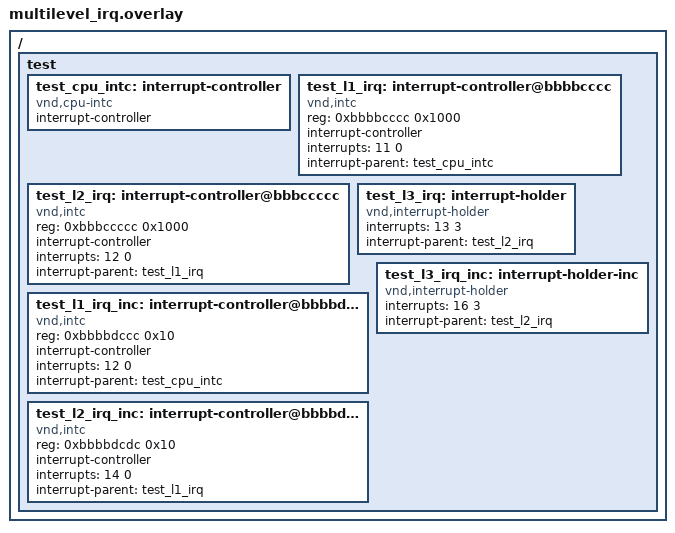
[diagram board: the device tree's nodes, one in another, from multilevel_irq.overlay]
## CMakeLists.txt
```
# SPDX-License-Identifier: Apache-2.0

cmake_minimum_required(VERSION 3.20.0)
find_package(Zephyr REQUIRED HINTS $ENV{ZEPHYR_BASE})
project(interrupt)

target_include_directories(app PRIVATE
  ${ZEPHYR_BASE}/kernel/include
  ${ZEPHYR_BASE}/arch/${ARCH}/include
  ${ZEPHYR_BASE}/arch/common/include
  )

target_sources(app PRIVATE
    src/prevent_irq.c
    src/interrupt_offload.c
    src/nested_irq.c
    )

target_sources_ifdef(CONFIG_DYNAMIC_INTERRUPTS app PRIVATE src/dynamic_isr.c)
target_sources_ifdef(CONFIG_X86 app PRIVATE src/regular_isr.c)
target_sources_ifdef(CONFIG_SHARED_INTERRUPTS app PRIVATE src/static_shared_irq.c)

if (CONFIG_SHARED_INTERRUPTS)
target_sources_ifdef(CONFIG_DYNAMIC_INTERRUPTS app PRIVATE src/dynamic_shared_irq.c)
endif()

if(CONFIG_MULTI_LEVEL_INTERRUPTS)
  target_sources_ifdef(CONFIG_DYNAMIC_INTERRUPTS app PRIVATE src/sw_isr_table.c)
  target_sources_ifdef(CONFIG_TEST_MULTILEVEL_IRQ app PRIVATE src/multilevel_irq.c)
endif()
```

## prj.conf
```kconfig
CONFIG_ZTEST=y
CONFIG_ZTEST_NEW_API=y
CONFIG_DYNAMIC_INTERRUPTS=y
CONFIG_MP_MAX_NUM_CPUS=1
CONFIG_THREAD_STACK_INFO=y
CONFIG_IRQ_OFFLOAD=y
```

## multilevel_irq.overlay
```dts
/*
 * Copyright (c) 2024 Meta Platforms
 * SPDX-License-Identifier: Apache-2.0
 */

/ {
	test {
		#address-cells = <0x1>;
		#size-cells = <0x1>;

		test_cpu_intc: interrupt-controller {
			compatible = "vnd,cpu-intc";
			#address-cells = <0>;
			#interrupt-cells = <0x01>;
			interrupt-controller;
		};

		test_l1_irq: interrupt-controller@bbbbcccc {
			compatible = "vnd,intc";
			reg = <0xbbbbcccc 0x1000>;
			interrupt-controller;
			#interrupt-cells = <2>;
			interrupts = <11 0>;
			interrupt-parent = <&test_cpu_intc>;
		};

		test_l2_irq: interrupt-controller@bbbccccc {
			compatible = "vnd,intc";
			reg = <0xbbbccccc 0x1000>;
			interrupt-controller;
			#interrupt-cells = <2>;
			interrupts = <12 0>;
			interrupt-parent = <&test_l1_irq>;
		};

		test_l3_irq: interrupt-holder {
			compatible = "vnd,interrupt-holder";
			status = "okay";
			interrupts = <13 3>;
			interrupt-parent = <&test_l2_irq>;
			interrupt-names = "test";
		};

		test_l1_irq_inc: interrupt-controller@bbbbdccc {
			compatible = "vnd,intc";
			reg = <0xbbbbdccc 0x10>;
			interrupt-controller;
			#interrupt-cells = <2>;
			interrupts = <12 0>;	/* +1 */
			interrupt-parent = <&test_cpu_intc>;
		};

		test_l2_irq_inc: interrupt-controller@bbbbdcdc {
			compatible = "vnd,intc";
			reg = <0xbbbbdcdc 0x10>;
			interrupt-controller;
			#interrupt-cells = <2>;
			interrupts = <14 0>;	/* +2 */
			interrupt-parent = <&test_l1_irq>;
		};

		test_l3_irq_inc: interrupt-holder-inc {
			compatible = "vnd,interrupt-holder";
			status = "okay";
			interrupts = <16 3>;	/* +3 */
			interrupt-parent = <&test_l2_irq>;
			interrupt-names = "test";
		};
	};
};
```

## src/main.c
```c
/*
 * Copyright (c) 2018 Intel Corporation
 *
 * SPDX-License-Identifier: Apache-2.0
 */

#include <ztest.h>

extern void test_isr_dynamic(void);
extern void test_nested_isr(void);
extern void test_prevent_interruption(void);
extern void test_isr_regular(void);
extern void test_isr_offload_job_multiple(void);
extern void test_isr_offload_job_identi(void);
extern void test_isr_offload_job(void);
extern void test_direct_interrupt(void);

void test_main(void)
{
	ztest_test_suite(interrupt_feature,
			ztest_unit_test(test_isr_dynamic),
			ztest_unit_test(test_nested_isr),
			ztest_unit_test(test_prevent_interruption),
			ztest_unit_test(test_isr_regular),
			ztest_unit_test(test_isr_offload_job_multiple),
			ztest_unit_test(test_isr_offload_job_identi),
			ztest_unit_test(test_isr_offload_job),
			ztest_unit_test(test_direct_interrupt)
			);
	ztest_run_test_suite(interrupt_feature);
}
```

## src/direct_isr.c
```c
/*
 * Copyright (c) 2021 Intel Corporation
 *
 * SPDX-License-Identifier: Apache-2.0
 */

#include <ztest.h>
#include "interrupt_util.h"

/*
 * Other arch has already been tested in testcase of gen_isr_table,
 * so we only test x86 and arch posix here.
 * And x86_64 is also not support this kind of interrupt, we skip it.
 */
#if (defined(CONFIG_X86) && !defined(CONFIG_X86_64)) ||\
	defined(CONFIG_ARCH_POSIX)

#if defined(CONFIG_X86)

#define TEST_DIRECT_IRQ_LINE_1	3
#define TEST_DIRECT_IRQ_LINE_2	4

#define TEST_DIRECT_IRQ_PRIO	0

#elif defined(CONFIG_ARCH_POSIX)
#define TEST_DIRECT_IRQ_LINE_1	5
#define TEST_DIRECT_IRQ_LINE_2	6

#define TEST_DIRECT_IRQ_PRIO	5

#endif

volatile uint32_t direct_int_executed[2];

ISR_DIRECT_DECLARE(direct_isr1)
{
	direct_int_executed[0]++;

	return 0;
}

ISR_DIRECT_DECLARE(direct_isr2)
{
	direct_int_executed[1]++;

	return 1;
}

/**
 * @brief Test direct interrupt function
 *
 * @details validate direct interrupt works as expected.
 * - Register two direct interrupt at build time.
 * - Trigger interrupt and check if isr handler has executed or not.
 * - Also check irq_enable and irq_disable works.
 *
 * @ingroup kernel_interrupt_tests
 *
 * @see IRQ_DIRECT_CONNECT(), ISR_DIRECT_DECLARE()
 */
void test_direct_interrupt(void)
{
	int trig_vec1, trig_vec2;

	IRQ_DIRECT_CONNECT(TEST_DIRECT_IRQ_LINE_1, TEST_DIRECT_IRQ_PRIO, direct_isr1, 0);
	IRQ_DIRECT_CONNECT(TEST_DIRECT_IRQ_LINE_2, TEST_DIRECT_IRQ_PRIO, direct_isr2, 0);

#if defined(CONFIG_X86)
	trig_vec1 = Z_IRQ_TO_INTERRUPT_VECTOR(TEST_DIRECT_IRQ_LINE_1);
	trig_vec2 = Z_IRQ_TO_INTERRUPT_VECTOR(TEST_DIRECT_IRQ_LINE_2);
#elif defined(CONFIG_ARCH_POSIX)
	trig_vec1 = TEST_DIRECT_IRQ_LINE_1;
	trig_vec2 = TEST_DIRECT_IRQ_LINE_2;
#endif
	TC_PRINT("irq(%d)=vector(%d)\n", TEST_DIRECT_IRQ_LINE_1, trig_vec1);
	TC_PRINT("irq(%d)=vector(%d)\n", TEST_DIRECT_IRQ_LINE_2, trig_vec2);

	irq_enable(TEST_DIRECT_IRQ_LINE_1);
	irq_enable(TEST_DIRECT_IRQ_LINE_2);

	zassert_true(direct_int_executed[0] == 0 &&
			direct_int_executed[1] == 0,
			"Both ISR should not execute");

	trigger_irq(trig_vec1);

	zassert_true(direct_int_executed[0] == 1 &&
			direct_int_executed[1] == 0,
			"ISR1 should execute");

	trigger_irq(trig_vec2);

	zassert_true(direct_int_executed[0] == 1 &&
			direct_int_executed[1] == 1,
			"Both ISR should execute");

	unsigned int key = irq_lock();

	/* trigger under irq locked */
	trigger_irq(trig_vec1);
	trigger_irq(trig_vec2);

	zassert_true(direct_int_executed[0] == 1 &&
			direct_int_executed[1] == 1,
			"Both ISR should not execute again");

	irq_unlock(key);

	/* interrupt serve after irq unlocked */
	zassert_true(direct_int_executed[0] == 2 &&
			direct_int_executed[1] == 2,
			"Both ISR should execute again(%d)(%d)",
			direct_int_executed[0], direct_int_executed[1]);

	/* trigger after irq unlocked */
	trigger_irq(trig_vec1);
	trigger_irq(trig_vec2);

	zassert_true(direct_int_executed[0] == 3 &&
			direct_int_executed[1] == 3,
			"Both ISR should execute again(%d)(%d)",
			direct_int_executed[0], direct_int_executed[1]);
}
#else
void test_direct_interrupt(void)
{
	ztest_test_skip();
}
#endif /* end defined(CONFIG_X86) || defined(CONFIG_ARCH_POSIX) */
```

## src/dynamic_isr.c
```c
/*
 * Copyright (c) 2018 Intel Corporation
 *
 * SPDX-License-Identifier: Apache-2.0
 */

#include <zephyr/ztest.h>
#include <zephyr/interrupt_util.h>

#define ISR_DYN_ARG	0xab249cfd

static unsigned int handler_has_run;
static uintptr_t handler_test_result;

static void dyn_isr(const void *arg)
{
	ARG_UNUSED(arg);
	handler_test_result = (uintptr_t)arg;
	handler_has_run++;
}

#if defined(CONFIG_GEN_SW_ISR_TABLE)
extern struct _isr_table_entry _sw_isr_table[];

#if defined(CONFIG_RISCV_RESERVED_IRQ_ISR_TABLES_OFFSET)
#define IRQ_OFFSET CONFIG_RISCV_RESERVED_IRQ_ISR_TABLES_OFFSET
#else
#define IRQ_OFFSET 0
#endif

/**
 * @brief Test dynamic ISR installation
 *
 * @ingroup kernel_interrupt_tests
 *
 * @details This routine locates an unused entry in the software ISR table,
 * installs a dynamic ISR to the unused entry by calling the dynamic
 * configured function, and verifies that the ISR is successfully installed
 * by checking the software ISR table entry.
 *
 * @see arch_irq_connect_dynamic()
 */
ZTEST(interrupt_feature, test_isr_dynamic)
{
	int i;
	const void *argval;

	for (i = 0; i < (CONFIG_NUM_IRQS - CONFIG_GEN_IRQ_START_VECTOR); i++) {
		if (_sw_isr_table[i].isr == z_irq_spurious) {
			break;
		}
	}

	zassert_true(_sw_isr_table[i].isr == z_irq_spurious,
		     "could not find slot for dynamic isr");

	printk("installing dynamic ISR for IRQ %d\n",
	       CONFIG_GEN_IRQ_START_VECTOR + i);

	argval = (const void *)&i;
	arch_irq_connect_dynamic(i + CONFIG_GEN_IRQ_START_VECTOR, 0, dyn_isr,
				 argval, 0);

	zassert_true(_sw_isr_table[i + IRQ_OFFSET].isr == dyn_isr &&
		     _sw_isr_table[i + IRQ_OFFSET].arg == argval,
		     "dynamic isr did not install successfully");
}
#else
/*
 * For testing arch such as x86, x86_64 and posix which support dynamic
 * interrupt but without SW ISR table, we test it by applying for a
 * dynamic interrupt and then trigger it to check if happened correctly.
 */
#if defined(CONFIG_X86)
#define IV_IRQS 32	/* start of vectors available for x86 IRQs */
#define TEST_IRQ_DYN_LINE 25

#elif defined(CONFIG_ARCH_POSIX)
#define TEST_IRQ_DYN_LINE 5
#endif

ZTEST(interrupt_feature, test_isr_dynamic)
{
	int vector_num;

	/**TESTPOINT: configuration of interrupts dynamically at runtime */
	vector_num = arch_irq_connect_dynamic(TEST_IRQ_DYN_LINE, 1, dyn_isr,
				 (void *)ISR_DYN_ARG, 0);

#if defined(CONFIG_X86_64)
/* The isr table for x86_64 is visiable, so check it up here */
extern void (*x86_irq_funcs[])(const void *);
extern const void *x86_irq_args[];

	zassert_true(x86_irq_funcs[vector_num - IV_IRQS] == dyn_isr &&
		     x86_irq_args[vector_num - IV_IRQS] == (void *)ISR_DYN_ARG,
		     "dynamic isr did not install successfully");
#endif

	TC_PRINT("vector(%d)\n", vector_num);
	zassert_true(vector_num > 0,
			"irq connect dynamic failed");

	zassert_equal(handler_has_run, 0,
			"handler has run before interrupt trigger");

	irq_enable(TEST_IRQ_DYN_LINE);

	trigger_irq(vector_num);

	zassert_equal(handler_has_run, 1,
			"interrupt triggered but handler has not run(%d)",
			handler_has_run);

	/**TESTPOINT: pass word-sized parameter to interrupt */
	zassert_equal(handler_test_result, ISR_DYN_ARG,
			"parameter(0x%" PRIxPTR ") in handler is not correct",
			handler_test_result);

	trigger_irq(vector_num);

	/**TESTPOINT: interrupt triggered again */
	zassert_equal(handler_has_run, 2,
			"interrupt triggered but handler has not run(%d)",
			handler_has_run);

	irq_disable(TEST_IRQ_DYN_LINE);
}
#endif /* CONFIG_GEN_SW_ISR_TABLE */
```

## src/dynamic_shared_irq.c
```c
/*
 * Copyright 2023 NXP
 *
 * SPDX-License-Identifier: Apache-2.0
 */

#include "test_shared_irq.h"

struct shared_irq_fixture {
	unsigned int irq1;
	unsigned int irq2;
	unsigned int irq1_table_idx;
	unsigned int irq2_table_idx;
	unsigned int irq_priority;
};

static struct shared_irq_fixture fixture;

static void reset_test_vector(void)
{
	int i;

	for (i = 0; i < TEST_VECTOR_SIZE; i++) {
		test_vector[i] = 0;
	}
}

static void dynamic_shared_irq_suite_after(void *data)
{
	ARG_UNUSED(data);

	/* note: no need to check the state of the SW ISR tables after
	 * all these disconnect operations. If there's something wrong
	 * it should be detected by dynamic_shared_irq_suite_before().
	 */
	arch_irq_disconnect_dynamic(fixture.irq1, fixture.irq_priority,
				    test_isr_0, 0, 0);
	arch_irq_disconnect_dynamic(fixture.irq1, fixture.irq_priority,
				    test_isr_1, (void *)1, 0);
	arch_irq_disconnect_dynamic(fixture.irq2, fixture.irq_priority,
				    test_isr_2, (void *)2, 0);
}

static void dummy_isr(const void *data)
{
	ARG_UNUSED(data);

	test_vector[0] = TEST_DUMMY_ISR_VAL;
}

static unsigned int get_irq_slot(unsigned int start)
{
	unsigned int i, table_idx;

	for (i = start; i <= CONFIG_GEN_IRQ_START_VECTOR + CONFIG_NUM_IRQS - 1; i++) {
		table_idx = i - CONFIG_GEN_IRQ_START_VECTOR;

		if (_sw_isr_table[table_idx].isr == &z_irq_spurious) {
			test_vector[0] = 0;

			/* check to see if we can trigger this IRQ */
			arch_irq_connect_dynamic(i, IRQ_PRIORITY, dummy_isr,
						 NULL, IRQ_FLAGS);
			irq_enable(i);
			trigger_irq(i);

			/* wait a bit */
			k_busy_wait(100);

			if (test_vector[0] == TEST_DUMMY_ISR_VAL) {
				/* found a valid INTID */
				irq_disable(i);

				arch_irq_disconnect_dynamic(i, IRQ_PRIORITY,
							    dummy_isr, NULL, 0);
				return i;
			}
		}
	}

	return TEST_INVALID_IRQ;
}

#if defined(CONFIG_RISCV_RESERVED_IRQ_ISR_TABLES_OFFSET)
#define TABLE_OFFSET CONFIG_RISCV_RESERVED_IRQ_ISR_TABLES_OFFSET
#else
#define TABLE_OFFSET 0
#endif

static void *dynamic_shared_irq_suite_setup(void)
{
	fixture.irq1 = get_irq_slot(CONFIG_GEN_IRQ_START_VECTOR + TABLE_OFFSET);
	zassert_true(fixture.irq1 != TEST_INVALID_IRQ,
		     "no suitable value found for irq1");
	fixture.irq2 = get_irq_slot(fixture.irq1 + 1);
	zassert_true(fixture.irq2 != TEST_INVALID_IRQ,
		     "no suitable value found for irq2");
	fixture.irq_priority = IRQ_PRIORITY;

	fixture.irq1_table_idx = fixture.irq1 - CONFIG_GEN_IRQ_START_VECTOR;
	fixture.irq2_table_idx = fixture.irq2 - CONFIG_GEN_IRQ_START_VECTOR;

	return NULL;
}

static void dynamic_shared_irq_suite_before(void *data)
{
	ARG_UNUSED(data);

	arch_irq_connect_dynamic(fixture.irq1, fixture.irq_priority,
				 test_isr_0, 0, IRQ_FLAGS);

	zassert_true(_sw_isr_table[fixture.irq1_table_idx + TABLE_OFFSET].isr == test_isr_0,
		     "wrong _sw_isr_table ISR at irq1");
	zassert_true(!_sw_isr_table[fixture.irq1_table_idx + TABLE_OFFSET].arg,
		     "wrong _sw_isr_table argument at irq1");
	zassert_true(!z_shared_sw_isr_table[fixture.irq1_table_idx + TABLE_OFFSET].client_num,
		     "wrong client number at irq1");

	arch_irq_connect_dynamic(fixture.irq1, fixture.irq_priority,
				 test_isr_1, (void *)1, IRQ_FLAGS);

	zassert_true(_sw_isr_table[fixture.irq1_table_idx + TABLE_OFFSET].isr == z_shared_isr,
		     "wrong _sw_isr_table ISR at irq1");
	zassert_true(_sw_isr_table[fixture.irq1_table_idx + TABLE_OFFSET].arg ==
		     &z_shared_sw_isr_table[fixture.irq1_table_idx + TABLE_OFFSET],
		     "wrong _sw_isr_table argument at irq1");
	zassert_true(z_shared_sw_isr_table[fixture.irq1_table_idx + TABLE_OFFSET].client_num == 2,
		     "wrong client number at irq1");

	zassert_true(client_exists_at_index(test_isr_0, 0, fixture.irq1_table_idx + TABLE_OFFSET,
					    0),
		     "unexpected client data for irq1, index 0");
	zassert_true(client_exists_at_index(test_isr_1, (void *)1,
		     fixture.irq1_table_idx + TABLE_OFFSET, 1),
		     "unexpected client data for irq1, index 1");

	arch_irq_connect_dynamic(fixture.irq2, fixture.irq_priority,
				 test_isr_2, (void *)2, IRQ_FLAGS);

	zassert_true(_sw_isr_table[fixture.irq2_table_idx + TABLE_OFFSET].isr == test_isr_2,
		     "wrong _sw_isr_table ISR at irq2");
	zassert_true(_sw_isr_table[fixture.irq2_table_idx + TABLE_OFFSET].arg == (void *)2,
		     "wrong _sw_isr_table argument at irq2");
	zassert_true(!z_shared_sw_isr_table[fixture.irq2_table_idx + TABLE_OFFSET].client_num,
		     "wrong client number at irq2");

	reset_test_vector();
}

/**
 * @brief Test writing to a vector with a shared interrupt
 *
 * @ingroup kernel_interrupt_tests
 *
 * @details This tests if interrupts are dynamically shared successfully
 * (i.e: multiple ISR/arg pairs are called whenever the interrupt
 * they were registered for is triggered).
 */
ZTEST(shared_irq_feature, test_dynamic_shared_irq_write)
{
	int i;

	irq_enable(fixture.irq1);
	irq_enable(fixture.irq2);

	trigger_irq(fixture.irq1);
	trigger_irq(fixture.irq2);

	/* wait 5ms before checking the results */
	k_busy_wait(5000);

	for (i = 0; i < TEST_VECTOR_SIZE; i++) {
		zassert_true(test_vector[i] == result_vector[i],
			     "wrong test_vector value at %d: 0x%x vs 0x%x",
			     i, test_vector[i], result_vector[i]);
	}

	irq_disable(fixture.irq1);
	irq_disable(fixture.irq2);
}

/**
 * @brief Test writing to a vector after an ISR/arg disconnect.
 *
 * @ingroup kernel_interrupt_tests
 *
 * @details This tests if ISR/arg pairs are disconnected successfully
 * and the interrupts are "unshared" whenever a single ISR/arg pair is
 * left.
 */
ZTEST(shared_irq_feature, test_dynamic_shared_irq_disconnect_write)
{
	int i;

	/* remove test_isr_0/NULL pair. After this statement we expect
	 * irq1 to be unshared.
	 */
	arch_irq_disconnect_dynamic(fixture.irq1, fixture.irq_priority,
				    test_isr_0, 0, 0);

	zassert_true(_sw_isr_table[fixture.irq1_table_idx + TABLE_OFFSET].isr == test_isr_1,
		     "wrong _sw_isr_table ISR at irq1");
	zassert_true(_sw_isr_table[fixture.irq1_table_idx + TABLE_OFFSET].arg == (void *)1,
		     "wrong _sw_isr_table arg at irq1");
	zassert_true(!z_shared_sw_isr_table[fixture.irq1_table_idx + TABLE_OFFSET].client_num,
		     "wrong client number at irq1");

	irq_enable(fixture.irq1);
	trigger_irq(fixture.irq1);

	/* wait 5ms before checking the results */
	k_busy_wait(5000);

	for (i = 0; i < TEST_VECTOR_SIZE; i++) {
		if (i == 1) {
			zassert_true(test_vector[i] == result_vector[i],
				     "wrong test_vector at %d: 0x%x vs 0x%x",
				     i, test_vector[i], result_vector[i]);
			continue;
		}

		zassert_true(!test_vector[i],
			     "wrong test_vector value at %d: 0x%x vs 0x%x",
			     i, test_vector[i], result_vector[i]);
	}

	irq_disable(fixture.irq1);
}

ZTEST_SUITE(shared_irq_feature, NULL,
	    dynamic_shared_irq_suite_setup,
	    dynamic_shared_irq_suite_before,
	    dynamic_shared_irq_suite_after,
	    NULL);
```

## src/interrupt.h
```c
/*
 * Copyright (c) 2018 Intel Corporation
 *
 * SPDX-License-Identifier: Apache-2.0
 */

#include <ztest.h>
#include <irq_offload.h>
#include <kernel_structs.h>


#if defined(CONFIG_CPU_CORTEX_M)
#include <arch/arm/aarch32/cortex_m/cmsis.h>

static u32_t get_available_nvic_line(u32_t initial_offset)
{
	int i;

	for (i = initial_offset - 1; i >= 0; i--) {

		if (NVIC_GetEnableIRQ(i) == 0) {
			/*
			 * Interrupts configured statically with IRQ_CONNECT(.)
			 * are automatically enabled. NVIC_GetEnableIRQ()
			 * returning false, here, implies that the IRQ line is
			 * either not implemented or it is not enabled, thus,
			 * currently not in use by Zephyr.
			 */

			/* Set the NVIC line to pending. */
			NVIC_SetPendingIRQ(i);

			if (NVIC_GetPendingIRQ(i)) {
				/* If the NVIC line is pending, it is
				 * guaranteed that it is implemented.
				 */
				break;
			}
		}
	}

	ztest_true(i >= 0, "No available IRQ line\n");

	return i;
}

static void trigger_irq(int irq)
{
	printk("Triggering irq : %d\n", irq);
#if defined(CONFIG_SOC_TI_LM3S6965_QEMU) || defined(CONFIG_CPU_CORTEX_M0) \
	|| defined(CONFIG_CPU_CORTEX_M0PLUS)
	NVIC_SetPendingIRQ(irq);
#else
	NVIC->STIR = irq;
#endif
}

#elif defined(CONFIG_RISCV)
static void trigger_irq(int irq)
{
	u32_t mip;

	printk("Triggering irq : %d\n", irq);
	__asm__ volatile ("csrrs %0, mip, %1\n"
			: "=r" (mip)
			: "r" (1 << irq));
}

#elif defined(CONFIG_CPU_ARCV2)
static void trigger_irq(int irq)
{
	printk("Triggering irq : %d\n", irq);
	z_arc_v2_aux_reg_write(_ARC_V2_AUX_IRQ_HINT, irq);
}
#else
/* for not supported architecture */
#define NO_TRIGGER_FROM_SW
#endif
```

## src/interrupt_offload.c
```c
/*
 * Copyright (c) 2021 Intel Corporation
 *
 * SPDX-License-Identifier: Apache-2.0
 */

#include <zephyr/ztest.h>
#include <zephyr/irq_offload.h>
#include <zephyr/interrupt_util.h>
#if defined(CONFIG_ARCH_POSIX)
#include <soc.h>
#endif

#define STACK_SIZE	1024
#define NUM_WORK	4

static struct k_work offload_work[NUM_WORK];
static struct k_work_q wq_queue;
static K_THREAD_STACK_DEFINE(wq_stack, STACK_SIZE);
static K_THREAD_STACK_DEFINE(tstack, STACK_SIZE);
static struct k_thread tdata;

static struct k_sem sync_sem;
static struct k_sem end_sem;
static bool wait_for_end;
static atomic_t submit_success;
static atomic_t offload_job_cnt;

/*
 * This global variable control if the priority of offload job
 * is greater than the original thread.
 */
static bool offload_job_prio_higher;

static volatile int orig_t_keep_run;

/* record the initialized interrupt vector for reuse */
static int vector_num;

enum {
	TEST_OFFLOAD_MULTI_JOBS,
	TEST_OFFLOAD_IDENTICAL_JOBS
};

struct interrupt_param {
	struct k_work *work;
};

static struct interrupt_param irq_param;

/* thread entry of doing offload job */
static void entry_offload_job(struct k_work *work)
{
	if (offload_job_prio_higher) {
		/*TESTPOINT: offload thread run right after irq end.*/
		zassert_equal(orig_t_keep_run, 0,
			"the offload did not run immediately.");
	} else {
		/*TESTPOINT: original thread run right after irq end.*/
		zassert_equal(orig_t_keep_run, 1,
			"the offload did not run immediately.");
	}

	atomic_inc(&offload_job_cnt);
	k_sem_give(&end_sem);
}

/* offload work to work queue */
void isr_handler(const void *param)
{
	struct k_work *work = ((struct interrupt_param *)param)->work;

	zassert_not_null(work, "kwork should not be NULL");

	orig_t_keep_run = 0;

	/* If the work is busy, we don't submit it. */
	if (!k_work_busy_get(work)) {
		zassert_equal(k_work_submit_to_queue(&wq_queue, work),
				1, "kwork not submitted or queued");

		atomic_inc(&submit_success);
	}
}

#if defined(CONFIG_DYNAMIC_INTERRUPTS)
/*
 * So far, we only test x86 and arch posix by real dynamic interrupt.
 * Other arch will be add later.
 */
#if defined(CONFIG_X86)
#define TEST_IRQ_DYN_LINE 26

#elif defined(CONFIG_ARCH_POSIX)
#if defined(OFFLOAD_SW_IRQ)
#define TEST_IRQ_DYN_LINE OFFLOAD_SW_IRQ
#else
#define TEST_IRQ_DYN_LINE 0
#endif

#elif defined(CONFIG_MICROBLAZE)
#define TEST_IRQ_DYN_LINE 1
#else
#define TEST_IRQ_DYN_LINE 0
#endif

#endif

static void init_dyn_interrupt(void)
{
	/* If we cannot get a dynamic interrupt, skip test. */
	if (TEST_IRQ_DYN_LINE == 0) {
		ztest_test_skip();
	}

	/* We just initialize dynamic interrupt once, then reuse them */
	if (!vector_num) {
		vector_num = irq_connect_dynamic(TEST_IRQ_DYN_LINE, 1,
					isr_handler, (void *)&irq_param, 0);
	}

	TC_PRINT("vector(%d)\n", vector_num);
	zassert_true(vector_num > 0, "no vector can be used");
	irq_enable(TEST_IRQ_DYN_LINE);
}

static void trigger_offload_interrupt(const bool real_irq, void *work)
{
	irq_param.work = work;

	if (real_irq) {
		trigger_irq(vector_num);
	} else {
		irq_offload((irq_offload_routine_t)&isr_handler, &irq_param);
	}
}

static void t_running(void *p1, void *p2, void *p3)
{
	ARG_UNUSED(p1);
	ARG_UNUSED(p2);
	ARG_UNUSED(p3);

	k_sem_give(&sync_sem);

	while (wait_for_end == false) {
		orig_t_keep_run = 1;
		k_usleep(150);
	}
}

static void init_env(int real_irq)
{
	static bool wq_already_start;

	/* semaphore used to sync the end */
	k_sem_init(&sync_sem, 0, 1);
	k_sem_init(&end_sem, 0, NUM_WORK);

	/* initialize global variables */
	submit_success = 0;
	offload_job_cnt = 0;
	orig_t_keep_run = 0;
	wait_for_end = false;

	/* initialize the dynamic interrupt while using it */
	if (real_irq && !vector_num) {
		init_dyn_interrupt();
	}

	/* initialize all the k_work */
	for (int i = 0; i < NUM_WORK; i++) {
		k_work_init(&offload_work[i], entry_offload_job);
	}

	/* start a work queue thread if not existing */
	if (!wq_already_start) {
		k_work_queue_start(&wq_queue, wq_stack, STACK_SIZE,
		K_PRIO_PREEMPT(1), NULL);

		wq_already_start = true;
	}
}

static void run_test_offload(int case_type, int real_irq)
{
	int thread_prio = K_PRIO_PREEMPT(0);

	/* initialize the global variables */
	init_env(real_irq);

	/* set priority of offload job higher than thread */
	if (offload_job_prio_higher) {
		thread_prio = K_PRIO_PREEMPT(2);
	}

	k_tid_t tid = k_thread_create(&tdata, tstack, STACK_SIZE,
			t_running,
			NULL, NULL, NULL, thread_prio,
			K_INHERIT_PERMS, K_NO_WAIT);

	/* wait for thread start */
	k_sem_take(&sync_sem, K_FOREVER);

	for (int i = 0; i < NUM_WORK; i++) {

		switch (case_type) {
		case TEST_OFFLOAD_MULTI_JOBS:
			trigger_offload_interrupt(real_irq,
					(void *)&offload_work[i]);
		break;
		case TEST_OFFLOAD_IDENTICAL_JOBS:
			trigger_offload_interrupt(real_irq,
					(void *)&offload_work[0]);
		break;
		default:
			ztest_test_fail();
		}
	}
	/* wait for all offload job complete */
	for (int i = 0; i < atomic_get(&submit_success); i++) {
		k_sem_take(&end_sem, K_FOREVER);
	}

	zassert_equal(submit_success, offload_job_cnt,
			"submitted job unmatch offload");

	/* notify the running thread to end */
	wait_for_end = true;

	k_thread_join(tid, K_FOREVER);
}

/**
 * @brief Test interrupt offload work to multiple jobs
 *
 * @ingroup kernel_interrupt_tests
 *
 * @details Validate isr can offload workload to multi work queue, and:
 *
 * - If the priority of the original thread < offload job, offload jobs
 *   could execute immediately.
 *
 * - If the priority of the original thread >= offload job, offload
 *   jobs will not execute immediately.
 *
 * We test this by irq_offload().
 */
ZTEST(interrupt_feature, test_isr_offload_job_multiple)
{
	offload_job_prio_higher = false;
	run_test_offload(TEST_OFFLOAD_MULTI_JOBS, false);

	offload_job_prio_higher = true;
	run_test_offload(TEST_OFFLOAD_MULTI_JOBS, false);
}

/**
 * @brief Test interrupt offload work to identical jobs
 *
 * @ingroup kernel_interrupt_tests
 *
 * @details Validate isr can offload workload to work queue, and all
 * the offload jobs use the same thread entry, and:
 *
 * - If the priority of the original thread < offload job, offload jobs
 *   could execute immediately.
 *
 * - If the priority of the original thread >= offload job, offload
 *   jobs will not execute immediately.
 *
 * We test this by irq_offload().
 */
ZTEST(interrupt_feature, test_isr_offload_job_identi)
{
	offload_job_prio_higher = false;
	run_test_offload(TEST_OFFLOAD_IDENTICAL_JOBS, false);

	offload_job_prio_higher = true;
	run_test_offload(TEST_OFFLOAD_IDENTICAL_JOBS, false);
}

/**
 * @brief Test interrupt offload work by dynamic interrupt
 *
 * @ingroup kernel_interrupt_tests
 *
 * @details Validate isr can offload workload to work queue, and the
 * offload jobs could execute immediately base on it's priority.
 * We test this by dynamic interrupt.
 */
ZTEST(interrupt_feature, test_isr_offload_job)
{
	if (!IS_ENABLED(CONFIG_DYNAMIC_INTERRUPTS)) {
		ztest_test_skip();
	}

	offload_job_prio_higher = true;
	run_test_offload(TEST_OFFLOAD_MULTI_JOBS, true);
	run_test_offload(TEST_OFFLOAD_IDENTICAL_JOBS, true);
}
```

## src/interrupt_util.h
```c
/*
 * Copyright (c) 2018 Intel Corporation
 *
 * SPDX-License-Identifier: Apache-2.0
 */

#ifndef INTERRUPT_UTIL_H_
#define INTERRUPT_UTIL_H_

#include <ztest.h>

#define MS_TO_US(ms)  (ms * USEC_PER_MSEC)

#if defined(CONFIG_CPU_CORTEX_M)
#include <arch/arm/aarch32/cortex_m/cmsis.h>

static inline uint32_t get_available_nvic_line(uint32_t initial_offset)
{
	int i;

	for (i = initial_offset - 1; i >= 0; i--) {

		if (NVIC_GetEnableIRQ(i) == 0) {
			/*
			 * Interrupts configured statically with IRQ_CONNECT(.)
			 * are automatically enabled. NVIC_GetEnableIRQ()
			 * returning false, here, implies that the IRQ line is
			 * either not implemented or it is not enabled, thus,
			 * currently not in use by Zephyr.
			 */

			/* Set the NVIC line to pending. */
			NVIC_SetPendingIRQ(i);

			if (NVIC_GetPendingIRQ(i)) {
				/*
				 * If the NVIC line is pending, it is
				 * guaranteed that it is implemented; clear the
				 * line.
				 */
				NVIC_ClearPendingIRQ(i);

				if (!NVIC_GetPendingIRQ(i)) {
					/*
					 * If the NVIC line can be successfully
					 * un-pended, it is guaranteed that it
					 * can be used for software interrupt
					 * triggering. Return the NVIC line
					 * number.
					 */
					break;
				}
			}
		}
	}

	zassert_true(i >= 0, "No available IRQ line\n");

	return i;
}

static inline void trigger_irq(int irq)
{
	printk("Triggering irq : %d\n", irq);
#if defined(CONFIG_SOC_TI_LM3S6965_QEMU) || defined(CONFIG_CPU_CORTEX_M0) \
	|| defined(CONFIG_CPU_CORTEX_M0PLUS) || defined(CONFIG_CPU_CORTEX_M1)
	NVIC_SetPendingIRQ(irq);
#else
	NVIC->STIR = irq;
#endif
}

#elif defined(CONFIG_GIC)
#include <drivers/interrupt_controller/gic.h>
#include <dt-bindings/interrupt-controller/arm-gic.h>

static inline void trigger_irq(int irq)
{
	printk("Triggering irq : %d\n", irq);

	/* Ensure that the specified IRQ number is a valid SGI interrupt ID */
	zassert_true(irq <= 15, "%u is not a valid SGI interrupt ID", irq);

	/*
	 * Generate a software generated interrupt and forward it to the
	 * requesting CPU.
	 */
#if CONFIG_GIC_VER <= 2
	sys_write32(GICD_SGIR_TGTFILT_REQONLY | GICD_SGIR_SGIINTID(irq),
		    GICD_SGIR);
#else
	gic_raise_sgi(irq, GET_MPIDR(), BIT(MPIDR_TO_CORE(GET_MPIDR())));
#endif
}

#elif defined(CONFIG_ARC)
static inline void trigger_irq(int irq)
{
	printk("Triggering irq : %d\n", irq);
	z_arc_v2_aux_reg_write(_ARC_V2_AUX_IRQ_HINT, irq);
}

#elif defined(CONFIG_X86)

#define TEST_IRQ_DYN_LINE 16
#define TEST_DYNAMIC_VECTOR     TEST_IRQ_DYN_LINE+32

static inline void trigger_irq(int irq)
{
	int vector = irq + 32;

/*
 * Trigger an interrupt of x86 under gcov code coverage report enabled,
 * which means GCC optimization will be -O0, so need to hard code the
 * immediate number for INT instruction. Otherwise, an build error
 * happends and shows:
 * "error: 'asm' operand 0 probably does not match constraints" and
 * "error: impossible constraint in 'asm'"
 */
#if defined(CONFIG_COVERAGE)
	if (vector == TEST_DYNAMIC_VECTOR) {
		__asm__ volatile("int %0" :: "i"(TEST_DYNAMIC_VECTOR));
	} else {
		printk("not interrupt");
	}
#else
	__asm__ volatile("int %0" :: "i"(vector));
#endif
}

#elif defined(CONFIG_ARCH_POSIX)
#include "irq_ctrl.h"

#define TEST_IRQ_DYN_LINE 5

static inline void trigger_irq(int irq)
{
	hw_irq_ctrl_raise_im_from_sw(irq);
}

#elif defined(CONFIG_RISCV)
static inline void trigger_irq(int irq)
{
	uint32_t mip;

	__asm__ volatile ("csrrs %0, mip, %1\n"
			  : "=r" (mip)
			  : "r" (1 << irq));
}

#elif defined(CONFIG_XTENSA)
static inline void trigger_irq(int irq)
{
	z_xt_set_intset(BIT((unsigned int)irq));
}

#elif defined(CONFIG_SPARC)
extern void z_sparc_enter_irq(int);

static inline void trigger_irq(int irq)
{
	z_sparc_enter_irq(irq);
}

#else
/* for not supported architecture */
#define NO_TRIGGER_FROM_SW
#endif

#endif /* INTERRUPT_UTIL_H_ */
```

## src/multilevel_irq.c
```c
/*
 * Copyright (c) 2024 Meta Platforms
 *
 * SPDX-License-Identifier: Apache-2.0
 */

#include <zephyr/devicetree.h>
#include <zephyr/irq.h>
#include <zephyr/irq_multilevel.h>
#include <zephyr/ztest.h>

ZTEST(interrupt_feature, test_multi_level_api)
{
	/* Zephyr multilevel-encoded IRQ */
	const uint32_t irqn_l3 = DT_IRQN(DT_NODELABEL(test_l3_irq));
	const uint32_t irqn_l2 = DT_IRQN(DT_NODELABEL(test_l2_irq));
	const uint32_t irqn_l1 = DT_IRQN(DT_NODELABEL(test_l1_irq));
	/* Raw IRQ specified in the devicetree */
	const uint32_t raw_l3 = DT_IRQ(DT_NODELABEL(test_l3_irq), irq);
	const uint32_t raw_l2 = DT_IRQ(DT_NODELABEL(test_l2_irq), irq);
	const uint32_t raw_l1 = DT_IRQ(DT_NODELABEL(test_l1_irq), irq);

	/**
	 *  - irq_get_level()
	 */
	zassert_equal(3, irq_get_level(irqn_l3));
	zassert_equal(2, irq_get_level(irqn_l2));
	zassert_equal(1, irq_get_level(irqn_l1));

	/**
	 *  - irq_from_level_2()
	 *  - irq_to_level_2()
	 *  - irq_parent_level_2()
	 */
	zassert_equal(irq_from_level_2(irqn_l3), raw_l2);
	zassert_equal(irq_from_level_2(irqn_l2), raw_l2);

	zassert_equal(irq_to_level_2(raw_l2) & irqn_l2, irq_to_level_2(raw_l2));

	zassert_equal(irq_parent_level_2(irqn_l2), raw_l1);

	/**
	 *  - irq_from_level_3()
	 *  - irq_to_level_3()
	 *  - irq_parent_level_3()
	 */
	zassert_equal(irq_from_level_3(irqn_l3), raw_l3);

	zassert_equal(irq_to_level_3(raw_l3) & irqn_l3, irq_to_level_3(raw_l3));

	zassert_equal(irq_parent_level_3(irqn_l3), raw_l2);

	/**
	 *  - irq_from_level()
	 *  - irq_to_level()
	 *  - irq_parent_level()
	 */
	zassert_equal(irq_from_level(irqn_l3, 2), raw_l2);
	zassert_equal(irq_from_level(irqn_l2, 2), raw_l2);
	zassert_equal(irq_from_level(irqn_l3, 3), raw_l3);

	zassert_equal(irq_to_level(raw_l2, 2) & irqn_l2, irq_to_level(raw_l2, 2));
	zassert_equal(irq_to_level(raw_l3, 3) & irqn_l3, irq_to_level(raw_l3, 3));

	zassert_equal(irq_parent_level(irqn_l2, 2), raw_l1);
	zassert_equal(irq_parent_level(irqn_l3, 3), raw_l2);

	/**
	 *  - irq_get_intc_irq()
	 */
	zassert_equal(irq_get_intc_irq(irqn_l3), irqn_l2);
	zassert_equal(irq_get_intc_irq(irqn_l2), irqn_l1);
	zassert_equal(irq_get_intc_irq(irqn_l1), irqn_l1);

	const uint32_t irqn_l3_inc = DT_IRQN(DT_NODELABEL(test_l3_irq_inc));
	const uint32_t irqn_l2_inc = DT_IRQN(DT_NODELABEL(test_l2_irq_inc));
	const uint32_t irqn_l1_inc = DT_IRQN(DT_NODELABEL(test_l1_irq_inc));

	/**
	 * - irq_increment()
	 */
	zassert_equal(irq_increment(irqn_l1, 1), irqn_l1_inc);
	zassert_equal(irq_increment(irqn_l2, 2), irqn_l2_inc);
	zassert_equal(irq_increment(irqn_l3, 3), irqn_l3_inc);
}

ZTEST_SUITE(gen_isr_table_multilevel, NULL, NULL, NULL, NULL, NULL);
```

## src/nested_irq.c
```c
/*
 * Copyright (c) 2020 Stephanos Ioannidis <root@stephanos.io>
 * Copyright (c) 2018 Intel Corporation
 *
 * SPDX-License-Identifier: Apache-2.0
 */

#include <zephyr/ztest.h>
#include <zephyr/interrupt_util.h>

/*
 * Run the nested interrupt test for the supported platforms only.
 */
#if defined(CONFIG_CPU_CORTEX_M) || defined(CONFIG_ARC) || \
	defined(CONFIG_GIC) || defined(CONFIG_NRFX_CLIC)
#define TEST_NESTED_ISR
#endif

#define DURATION	5

#define ISR0_TOKEN	0xDEADBEEF
#define ISR1_TOKEN	0xCAFEBABE

/*
 * This test uses two IRQ lines selected within the range of available IRQs on
 * the target SoC.  These IRQs are platform and interrupt controller-specific,
 * and must be specified for every supported platform.
 *
 * In terms of priority, the IRQ1 is triggered from the ISR of the IRQ0;
 * therefore, the priority of IRQ1 must be greater than that of the IRQ0.
 */
#if defined(CONFIG_CPU_CORTEX_M)
/*
 * For Cortex-M NVIC, unused and available IRQs are automatically detected when
 * the test is run.
 *
 * The IRQ priorities start at 1 because the priority 0 is reserved for the
 * SVCall exception and Zero-Latency IRQs (see `_EXCEPTION_RESERVED_PRIO`).
 */
#define IRQ0_PRIO	2
#define IRQ1_PRIO	1
#elif defined(CONFIG_GIC)
/*
 * For the platforms that use the ARM GIC, use the SGI (software generated
 * interrupt) lines 14 and 15 for testing.
 */
#define IRQ0_LINE	14
#define IRQ1_LINE	15

/*
 * Choose lower prio for IRQ0 and higher priority for IRQ1
 * Minimum legal value of GICC BPR is '3' ie  <gggg.ssss>
 * Hence choosing default priority and highest possible priority
 * '0x0' as the priorities so that the preemption rule applies
 * generically to all GIC versions and security states.
 */
#define IRQ0_PRIO	IRQ_DEFAULT_PRIORITY
#define IRQ1_PRIO	0x0
#elif defined(CONFIG_SOC_SERIES_NRF54LX) && defined(CONFIG_RISCV_CORE_NORDIC_VPR)
#define IRQ0_LINE	16
#define IRQ1_LINE	17

#define IRQ0_PRIO	1
#define IRQ1_PRIO	2
#elif defined(CONFIG_SOC_NRF54H20_CPUPPR)
#define IRQ0_LINE	14
#define IRQ1_LINE	15

#define IRQ0_PRIO	1
#define IRQ1_PRIO	2
#elif defined(CONFIG_SOC_NRF9280_CPUPPR)
#define IRQ0_LINE	14
#define IRQ1_LINE	15

#define IRQ0_PRIO	1
#define IRQ1_PRIO	2
#else
/*
 * For all the other platforms, use the last two available IRQ lines for
 * testing.
 */
#define IRQ0_LINE	(CONFIG_NUM_IRQS - 1)
#define IRQ1_LINE	(CONFIG_NUM_IRQS - 2)

#define IRQ0_PRIO	1
#define IRQ1_PRIO	0
#endif

#ifdef TEST_NESTED_ISR
static uint32_t irq_line_0;
static uint32_t irq_line_1;

static uint32_t isr0_result;
static uint32_t isr1_result;

void isr1(const void *param)
{
	ARG_UNUSED(param);

	printk("isr1: Enter\n");

	/* Set verification token */
	isr1_result = ISR1_TOKEN;

	printk("isr1: Leave\n");
}

void isr0(const void *param)
{
	ARG_UNUSED(param);

	printk("isr0: Enter\n");

	/* Set verification token */
	isr0_result = ISR0_TOKEN;

	/* Trigger nested IRQ 1 */
	trigger_irq(irq_line_1);

	/* Wait for interrupt */
	k_busy_wait(DURATION * USEC_PER_MSEC);

	/* Validate nested ISR result token */
	zassert_equal(isr1_result, ISR1_TOKEN, "isr1 did not execute");

	printk("isr0: Leave\n");
}

/**
 * @brief Test interrupt nesting
 *
 * @ingroup kernel_interrupt_tests
 *
 * This routine tests the interrupt nesting feature, which allows an ISR to be
 * preempted in mid-execution if a higher priority interrupt is signaled. The
 * lower priority ISR resumes execution once the higher priority ISR has
 * completed its processing.
 *
 * The expected control flow for this test is as follows:
 *
 * 1. [thread] Trigger IRQ 0 (lower priority)
 * 2. [isr0] Set ISR 0 result token and trigger IRQ 1 (higher priority)
 * 3. [isr1] Set ISR 1 result token and return
 * 4. [isr0] Validate ISR 1 result token and return
 * 5. [thread] Validate ISR 0 result token
 */
ZTEST(interrupt_feature, test_nested_isr)
{
	/* Resolve test IRQ line numbers */
#if defined(CONFIG_CPU_CORTEX_M)
	irq_line_0 = get_available_nvic_line(CONFIG_NUM_IRQS);
	irq_line_1 = get_available_nvic_line(irq_line_0);
#else
	irq_line_0 = IRQ0_LINE;
	irq_line_1 = IRQ1_LINE;
#endif

	/* Connect and enable test IRQs */
	arch_irq_connect_dynamic(irq_line_0, IRQ0_PRIO, isr0, NULL, 0);
	arch_irq_connect_dynamic(irq_line_1, IRQ1_PRIO, isr1, NULL, 0);

	irq_enable(irq_line_0);
	irq_enable(irq_line_1);

	/* Trigger test IRQ 0 */
	trigger_irq(irq_line_0);

	/* Wait for interrupt */
	k_busy_wait(DURATION * USEC_PER_MSEC);

	/* Validate ISR result token */
	zassert_equal(isr0_result, ISR0_TOKEN, "isr0 did not execute");
}
#else
ZTEST(interrupt_feature, test_nested_isr)
{
	ztest_test_skip();
}
#endif /* TEST_NESTED_ISR */
```

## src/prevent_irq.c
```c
/*
 * Copyright (c) 2018 Intel Corporation
 *
 * SPDX-License-Identifier: Apache-2.0
 */

#include <ztest.h>
#include <interrupt_util.h>

#define DURATION	5
#define HANDLER_TOKEN	0xDEADBEEF

/* Long enough to be guaranteed a tick "should have fired" */
#define TIMER_DELAY_US (128 * 1000000 / CONFIG_SYS_CLOCK_TICKS_PER_SEC)

static struct k_timer irqlock_timer;
volatile uint32_t handler_result;

static void timer_handler(struct k_timer *timer)
{
	ARG_UNUSED(timer);
	handler_result = HANDLER_TOKEN;
	printk("timer fired\n");
}

/**
 * @brief Test interrupt prevention
 *
 * @ingroup kernel_interrupt_tests
 *
 * This routine tests if the kernel is capable of preventing interruption, by
 * locking interrupts and busy-waiting to see if the system timer interrupt is
 * serviced while interrupts are locked; in addition, this test also verifies
 * that the system timer interrupt is serviced after interrupts are unlocked.
 */
ZTEST(interrupt_feature, test_prevent_interruption)
{
	unsigned int key;

	printk("locking interrupts\n");
	key = irq_lock();

	handler_result = 0;

	k_timer_init(&irqlock_timer, timer_handler, NULL);

	/* Start the timer and busy-wait for a bit with IRQs locked. The
	 * timer ought to have fired during this time if interrupts weren't
	 * locked -- but since they are, check_lock_new isn't updated.
	 */
	k_timer_start(&irqlock_timer, K_MSEC(DURATION), K_NO_WAIT);
	k_busy_wait(TIMER_DELAY_US);
	zassert_not_equal(handler_result, HANDLER_TOKEN,
		"timer interrupt was serviced while interrupts are locked");

	printk("unlocking interrupts\n");
	irq_unlock(key);

	k_busy_wait(TIMER_DELAY_US);

	zassert_equal(handler_result, HANDLER_TOKEN,
		"timer should have fired");

	k_timer_stop(&irqlock_timer);
}

ZTEST_SUITE(interrupt_feature, NULL, NULL, NULL, NULL, NULL);
```

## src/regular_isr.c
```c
/*
 * Copyright (c) 2021 Intel Corporation
 *
 * SPDX-License-Identifier: Apache-2.0
 */

#include <zephyr/ztest.h>
#include <zephyr/interrupt_util.h>
#include <zephyr/irq.h>

/*
 * Other arch has already been tested in testcase of gen_isr_table,
 * so we only test x86 series here.
 */

#define TEST_IRQ_LINE_1	27
#define TEST_IRQ_LINE_2	28

#define TEST_IRQ_PRIO	2


volatile uint32_t reg_int_executed[2];

void isr_comm(const void *param)
{
	int choice = POINTER_TO_INT(param);

	switch (choice) {
	case TEST_IRQ_LINE_1:
		reg_int_executed[0]++;
	break;
	case TEST_IRQ_LINE_2:
		reg_int_executed[1]++;
	break;

	default:
	break;
	}
}

/**
 * @brief Test regular interrupt
 *
 * @details Validate regular interrupt works as expected.
 * - Register two regular interrupt at build time.
 * - Trigger interrupt and check if isr handler has executed or not.
 * - Also check irq_enable and irq_disable works.
 *
 * @ingroup kernel_interrupt_tests
 *
 * @see IRQ_CONNECT(), irq_enable(), irq_disable(),
 * irq_unlock(),
 */
ZTEST(interrupt_feature, test_isr_regular)
{
	int trig_vec1, trig_vec2;

	IRQ_CONNECT(TEST_IRQ_LINE_1, TEST_IRQ_PRIO, isr_comm, (void *)TEST_IRQ_LINE_1, 0);
	IRQ_CONNECT(TEST_IRQ_LINE_2, TEST_IRQ_PRIO, isr_comm, (void *)TEST_IRQ_LINE_2, 0);

	trig_vec1 = Z_IRQ_TO_INTERRUPT_VECTOR(TEST_IRQ_LINE_1);
	trig_vec2 = Z_IRQ_TO_INTERRUPT_VECTOR(TEST_IRQ_LINE_2);

	TC_PRINT("irq(%d)=vector(%d)\n", TEST_IRQ_LINE_1, trig_vec1);
	TC_PRINT("irq(%d)=vector(%d)\n", TEST_IRQ_LINE_2, trig_vec2);

	irq_enable(TEST_IRQ_LINE_1);
	irq_enable(TEST_IRQ_LINE_2);

	trigger_irq(trig_vec1);

	zassert_true(reg_int_executed[0] == 1 &&
			reg_int_executed[1] == 0,
			"ISR1 should execute");

	trigger_irq(trig_vec2);

	zassert_true(reg_int_executed[0] == 1 &&
			reg_int_executed[1] == 1,
			"Both ISR should execute");

	unsigned int key = irq_lock();

	/* trigger under irq locked */
	trigger_irq(trig_vec1);
	trigger_irq(trig_vec2);

	zassert_true(reg_int_executed[0] == 1 &&
			reg_int_executed[1] == 1,
			"Both ISR should not execute again(%d)(%d)",
			reg_int_executed[0], reg_int_executed[1]);

	irq_unlock(key);

#ifdef CONFIG_BOARD_QEMU_X86
	/* QEMU seems to have an issue in that interrupts seem to post on
	 * the instruction after the 'sti' that is part of irq_unlock().  This
	 * can cause an issue if the instruction after the 'sti' ends up looking
	 * at the state that the ISR is suppose to update.  This has been shown
	 * to happen when building this test for LLVM.
	 *
	 * Adding a nop instruction allows QEMU to post the ISR before any state
	 * gets examined as a workaround.
	 *
	 * See GitHub issue zephyrproject-rtos/sdk-ng#629 for the qemu bug.
	 */
	arch_nop();
#endif

	/* interrupt serve after irq unlocked */
	zassert_true(reg_int_executed[0] == 2 &&
			reg_int_executed[1] == 2,
			"Both ISR should execute again(%d)(%d)",
			reg_int_executed[0], reg_int_executed[1]);

	/* trigger after irq unlocked */
	trigger_irq(trig_vec1);
	trigger_irq(trig_vec2);

	zassert_true(reg_int_executed[0] == 3 &&
			reg_int_executed[1] == 3,
			"Both ISR should execute again(%d)(%d)",
			reg_int_executed[0], reg_int_executed[1]);
}
```

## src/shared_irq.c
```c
/*
 * Copyright 2022 The Chromium OS Authors
 *
 * SPDX-License-Identifier: Apache-2.0
 */

#include <zephyr/ztest.h>
#include <zephyr/interrupt_util.h>

#define DURATION        5

#if defined(CONFIG_GIC)
#define ISR0_OFFSET	10
#define ISR1_2_OFFSET	11
#define ISR3_4_5_OFFSET	12
#define ISR6_OFFSET	13
#else
/* Offset for the interrupt used in this test. */
#define ISR0_OFFSET     (CONFIG_NUM_IRQS - 7)
#define ISR1_2_OFFSET   (CONFIG_NUM_IRQS - 6)
#define ISR3_4_5_OFFSET (CONFIG_NUM_IRQS - 5)
#define ISR6_OFFSET     (CONFIG_NUM_IRQS - 4)
#endif

#define MAX_ISR_TESTS 7

static volatile int test_flag[MAX_ISR_TESTS] = {0};

static void isr0(void *arg)
{
	int value = POINTER_TO_INT(arg);

	test_flag[0] = value;
}

static void share_isr1(void *arg)
{
	int value = POINTER_TO_INT(arg);

	test_flag[1] = value;
}

static void share_isr2(void *arg)
{
	int value = POINTER_TO_INT(arg);

	test_flag[2] = value;
}

static void share_isr3(void *arg)
{
	int value = POINTER_TO_INT(arg);

	test_flag[3] = value;
}

static void share_isr4(void *arg)
{
	int value = POINTER_TO_INT(arg);

	test_flag[4] = value;
}

static void share_isr5(void *arg)
{
	int value = POINTER_TO_INT(arg);

	test_flag[5] = value;
}

static void isr6(void *arg)
{
	int value = POINTER_TO_INT(arg);

	test_flag[6] = value;
}

/**
 * @brief Test shared interrupt
 *
 * @details Validate that shared interrupts work as expected.
 * - Register two regular interrupt at build time.
 * - Two shared interrupts at build time.
 * - Three shared interrupts at build time.
 * - Trigger interrupts and check if isrs handler are executed or not.
 *
 * @ingroup kernel_interrupt_tests
 */
ZTEST(interrupt_feature, test_shared_irq)
{
	/* Ensure the IRQ is disabled before enabling it at run time */
	irq_disable(ISR0_OFFSET);
	irq_disable(ISR1_2_OFFSET);
	irq_disable(ISR3_4_5_OFFSET);
	irq_disable(ISR6_OFFSET);

	/* Place the non-direct shared interrupts */
	IRQ_CONNECT(ISR0_OFFSET,     0, isr0,       (void *)1, 0);
	IRQ_CONNECT(ISR1_2_OFFSET,   0, share_isr1, (void *)2, 0);
	IRQ_CONNECT(ISR1_2_OFFSET,   0, share_isr2, (void *)3, 0);
	IRQ_CONNECT(ISR3_4_5_OFFSET, 0, share_isr3, (void *)4, 0);
	IRQ_CONNECT(ISR3_4_5_OFFSET, 0, share_isr4, (void *)5, 0);
	IRQ_CONNECT(ISR3_4_5_OFFSET, 0, share_isr5, (void *)6, 0);
	IRQ_CONNECT(ISR6_OFFSET,     0, isr6,       (void *)7, 0);

	/* Enable and pend the interrupts */
	irq_enable(ISR0_OFFSET);
	irq_enable(ISR1_2_OFFSET);
	irq_enable(ISR3_4_5_OFFSET);
	irq_enable(ISR6_OFFSET);

	/* Trigger the interrupts */
	trigger_irq(ISR0_OFFSET);
	trigger_irq(ISR1_2_OFFSET);
	trigger_irq(ISR3_4_5_OFFSET);
	trigger_irq(ISR6_OFFSET);
	k_busy_wait(MS_TO_US(DURATION));

	for (int i = 0; i < MAX_ISR_TESTS; i++) {
		zassert_true(test_flag[i] == i + 1, "Test flag not set by ISR%d\n", i);
	}
}
```
